# STM32F429xx register map
File version: 1.0
Registers are 32-bit, read-write, reset 0x0 unless marked. A register's access mark holds for its fields unless they carry their own. Offsets are from the block's base; [hi:lo] are bit positions; {n}, {i} and the like mark numbered series.

## I2C1 — Inter-integrated Circuit Interface
Base 0x40005400
Same registers: I2C2 0x40005800, I2C3 0x40005C00
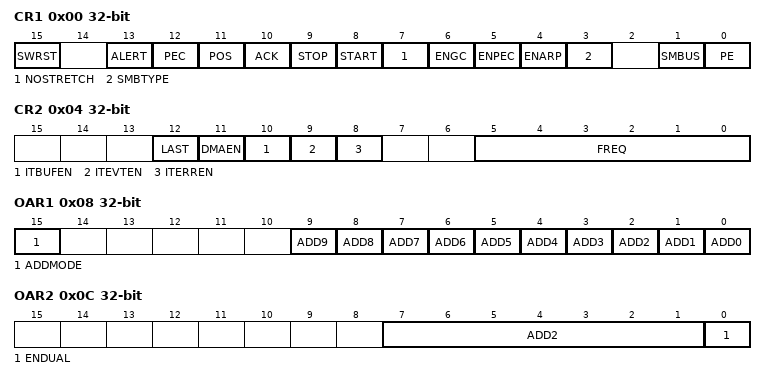
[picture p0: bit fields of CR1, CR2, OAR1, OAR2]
0x00 CR1 — I2C Control register 1
  [15] SWRST — Software Reset
  [13] ALERT — SMBus Alert
  [12] PEC — Packet Error Checking
  [11] POS — Acknowledge/PEC Position (for data reception)
  [10] ACK — Acknowledge Enable
    1=ACK (ACK is sent after current received byte.); 0=NACK (NACK is sent after current received byte.)
  [9] STOP — Stop Generation
  [8] START — Start Generation
  [7] NOSTRETCH — Clock Stretching Disable (Slave mode)
  [6] ENGC — General Call Enable
  [5] ENPEC — PEC Enable
  [4] ENARP — ARP Enable
  [3] SMBTYPE — SMBus Type
  [1] SMBUS — SMBus Mode
  [0] PE — Peripheral Enable
0x04 CR2 — I2C Control register 2
  [12] LAST — DMA Last Transfer
  [11] DMAEN — DMA Requests Enable
  [10] ITBUFEN — Buffer Interrupt Enable
  [9] ITEVTEN — Event Interrupt Enable
  [8] ITERREN — Error Interrupt Enable
  [5:0] FREQ — FREQ[5:0] bits (Peripheral Clock Frequency)
0x08 OAR1 — I2C Own address register 1
  [15] ADDMODE — Addressing Mode (Slave mode)
  [n] ADD{n} (n=0..9) — Bit {n}
0x0C OAR2 — I2C Own address register 2
  [7:1] ADD2 — Interface address
  [0] ENDUAL — Dual addressing mode enable
0x10 DR — I2C Data register
  [7:0] DR — 8-bit Data Register
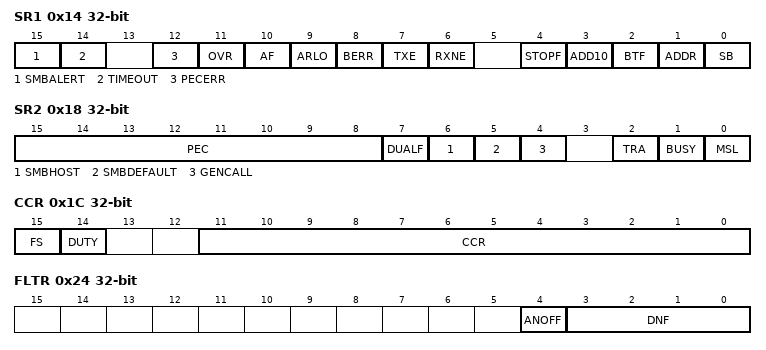
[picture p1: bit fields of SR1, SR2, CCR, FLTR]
0x14 SR1 — I2C Status register 1
  [15] SMBALERT — SMBus Alert
  [14] TIMEOUT — Timeout or Tlow Error
  [12] PECERR — PEC Error in reception
  [11] OVR — Overrun/Underrun
  [10] AF — Acknowledge Failure
  [9] ARLO — Arbitration Lost (master mode)
  [8] BERR — Bus Error
  [7] TXE — Data Register Empty (transmitters)
  [6] RXNE — Data Register not Empty (receivers)
  [4] STOPF — Stop detection (Slave mode)
  [3] ADD10 — 10-bit header sent (Master mode)
  [2] BTF — Byte Transfer Finished
  [1] ADDR — Address sent (master mode)/matched (slave mode)
  [0] SB — Start Bit (Master mode)
0x18 SR2 — I2C Status register 2
  [15:8] PEC — Packet Error Checking Register
  [7] DUALF — Dual Flag (Slave mode)
  [6] SMBHOST — SMBus Host Header (Slave mode)
  [5] SMBDEFAULT — SMBus Device Default Address (Slave mode)
  [4] GENCALL — General Call Address (Slave mode)
  [2] TRA — Transmitter/Receiver
    1=WRITE (Bus is in write transfer); 0=READ (Bus is in read transfer)
  [1] BUSY — Bus Busy
  [0] MSL — Master/Slave
0x1C CCR — I2C Clock control register
  [15] FS — I2C Master Mode Selection
    0=STANDARD_MODE (Master clock speed range is standard mode); 1=FAST_MODE (Master clock speed range is fast mode)
  [14] DUTY — Fast Mode Duty Cycle
    0=DUTYCYCLE_2 (I2C fast mode Tlow/Thigh = 2); 1=DUTYCYCLE_16_9 (I2C fast mode Tlow/Thigh = 16/9)
  [11:0] CCR — Clock Control Register in Fast/Standard mode (Master mode)
0x20 TRISE — I2C TRISE register
  [5:0] TRISE — Maximum Rise Time in Fast/Standard mode (Master mode)
0x24 FLTR — I2C FLTR register
  [4] ANOFF — Analog Noise Filter OFF
  [3:0] DNF — Digital Noise Filter

## PWR — Power Control
Base 0x40007000
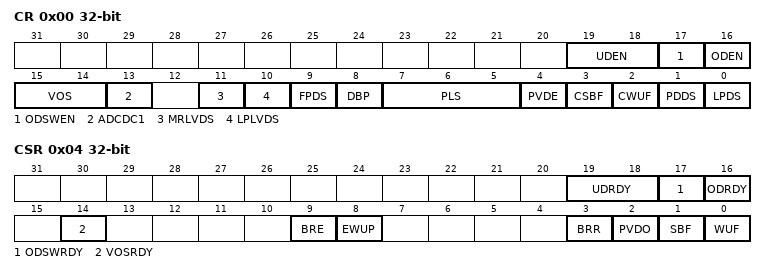
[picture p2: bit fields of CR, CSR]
0x00 CR — PWR power control register
  [19:18] UDEN — Under Drive enable in stop mode
  [17] ODSWEN — Over Drive switch enabled
  [16] ODEN — Over Drive enable
  [15:14] VOS — VOS[1:0] bits (Regulator voltage scaling output selection)
    3=SCALE1; 2=SCALE2; 1=SCALE3
  [13] ADCDC1 — Refer to AN4073 on how to use this bit
  [11] MRLVDS — Main regulator Low Voltage Scaling in Stop mode
  [10] LPLVDS — Low-Power Regulator Low Voltage Scaling in Stop mode
  [9] FPDS — Flash power down in Stop mode
  [8] DBP — Disable Backup Domain write protection
  [7:5] PLS — PLS[2:0] bits (PVD Level Selection)
    0=PVDLEVEL_0 (Voltage threshold detected by PVD 2.2 V); 1=PVDLEVEL_1 (Voltage threshold detected by PVD 2.3 V); 2=PVDLEVEL_2 (Voltage threshold detected by PVD 2.4 V); 3=PVDLEVEL_3 (Voltage threshold detected by PVD 2.5 V); 4=PVDLEVEL_4 (Voltage threshold detected by PVD 2.6 V); 5=PVDLEVEL_5 (Voltage threshold detected by PVD 2.7 V); 6=PVDLEVEL_6 (Voltage threshold detected by PVD 2.8 V); 7=PVDLEVEL_7 (Voltage threshold detected by PVD 2.9 V)
  [4] PVDE — Power Voltage Detector Enable
  [3] CSBF — Clear Standby Flag
  [2] CWUF — Clear Wakeup Flag
  [1] PDDS — Power Down Deepsleep
  [0] LPDS — Low-Power Deepsleep
    0=MAIN (Voltage Regulator in main mode during deepsleep mode); 1=LOW_POWER (Voltage Regulator in low-power mode during deepsleep mode)
0x04 CSR — PWR power control/status register
  [19:18] UDRDY — Under Drive ready
  [17] ODSWRDY — Over Drive Switch ready
  [16] ODRDY — Over Drive generator ready
  [14] VOSRDY — Regulator voltage scaling output selection ready
  [9] BRE — Backup regulator enable
  [8] EWUP — Enable WKUP pin
  [3] BRR — Backup regulator ready
  [2] PVDO — PVD Output
  [1] SBF — Standby Flag
  [0] WUF — Wakeup Flag
